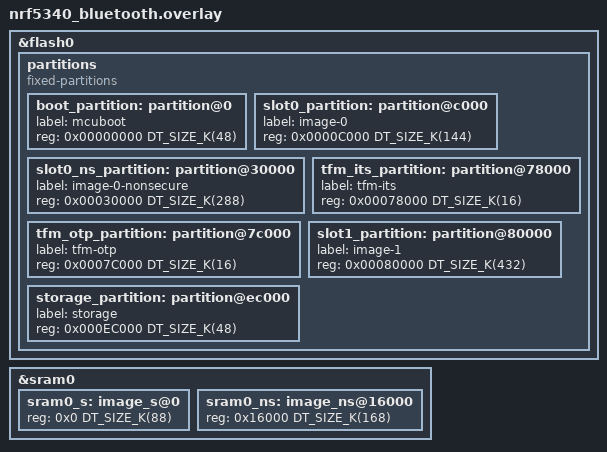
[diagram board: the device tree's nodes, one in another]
/*
 * Copyright (c) 2026 Nordic Semiconductor ASA
 *
 * SPDX-License-Identifier: LicenseRef-Nordic-5-Clause
 */

/*
 * Bluetooth-optimized TF-M partition layout for nRF5340
 *
 * nRF5340 has 1024 kB of flash and 512 kB of SRAM (application core).
 * TrustZone flash region alignment: 16 kB (SPU-based)
 * TrustZone RAM region alignment:    8 kB
 * Flash erase-block-size:            4 kB
 *
 * Optimized for Bluetooth LE applications with:
 * - Medium TF-M secure partition for BLE crypto
 * - MCUboot for BLE DFU (SMP/FOTA)
 * - ITS for bond storage and crypto keys
 * - Larger NS partition for BLE host stack + application
 * - NVS storage for BLE settings
 * - No Protected Storage (PS) to save flash
 *
 * Note: The nRF5340 network core runs the BLE controller
 * separately; this layout is for the application core only.
 *
 * Suitable for: BLE peripherals, BLE central, BLE mesh
 */

&flash0 {
	partitions {
		compatible = "fixed-partitions";
		#address-cells = <1>;
		#size-cells = <1>;

		/*
		 * Flash layout (S/NS boundaries 16 kB aligned):
		 *
		 * 0x00000000  MCUboot bootloader        (48 kB)
		 * 0x0000C000  Primary slot:
		 *   0x0000C000  TF-M secure image       (128 kB)
		 *   0x0002C000  Non-secure BLE app       (304 kB)
		 * 0x00078000  TF-M ITS                   (16 kB)
		 * 0x0007C000  TF-M OTP / NV counters     (16 kB)
		 * 0x00080000  Secondary slot            (432 kB)
		 * 0x000EC000  Non-secure storage (NVS)   (48 kB)
		 *
		 * S/NS boundary at 0x2C000 is not 16 kB aligned.
		 * The actual SPU boundary is at 0x30000 (192 kB).
		 * TF-M handles the alignment internally — the DTS
		 * addresses must still be 4 kB aligned (erase block).
		 *
		 * CORRECTED: Ensure S/NS boundary at 16 kB alignment.
		 * slot0_partition ends at 0x2C000 -> round up to 0x30000.
		 */

		boot_partition: partition@0 {
			label = "mcuboot";
			reg = <0x00000000 DT_SIZE_K(48)>;
		};

		slot0_partition: partition@c000 {
			label = "image-0";
			reg = <0x0000C000 DT_SIZE_K(144)>;
		};

		slot0_ns_partition: partition@30000 {
			label = "image-0-nonsecure";
			reg = <0x00030000 DT_SIZE_K(288)>;
		};

		tfm_its_partition: partition@78000 {
			label = "tfm-its";
			reg = <0x00078000 DT_SIZE_K(16)>;
		};

		tfm_otp_partition: partition@7c000 {
			label = "tfm-otp";
			reg = <0x0007C000 DT_SIZE_K(16)>;
		};

		slot1_partition: partition@80000 {
			label = "image-1";
			reg = <0x00080000 DT_SIZE_K(432)>;
		};

		storage_partition: partition@ec000 {
			label = "storage";
			reg = <0x000EC000 DT_SIZE_K(48)>;
		};
	};
};

&sram0 {
	sram0_s: image_s@0 {
		#address-cells = <1>;
		#size-cells = <1>;
		/* 88 kB secure — 8 kB aligned */
		reg = <0x0 DT_SIZE_K(88)>;
		ranges = <0x0 0x0 DT_SIZE_K(88)>;
	};

	sram0_ns: image_ns@16000 {
		#address-cells = <1>;
		#size-cells = <1>;
		/* 168 kB non-secure — rest for BLE host stack */
		reg = <0x16000 DT_SIZE_K(168)>;
		ranges = <0x0 0x16000 DT_SIZE_K(168)>;
	};
};
